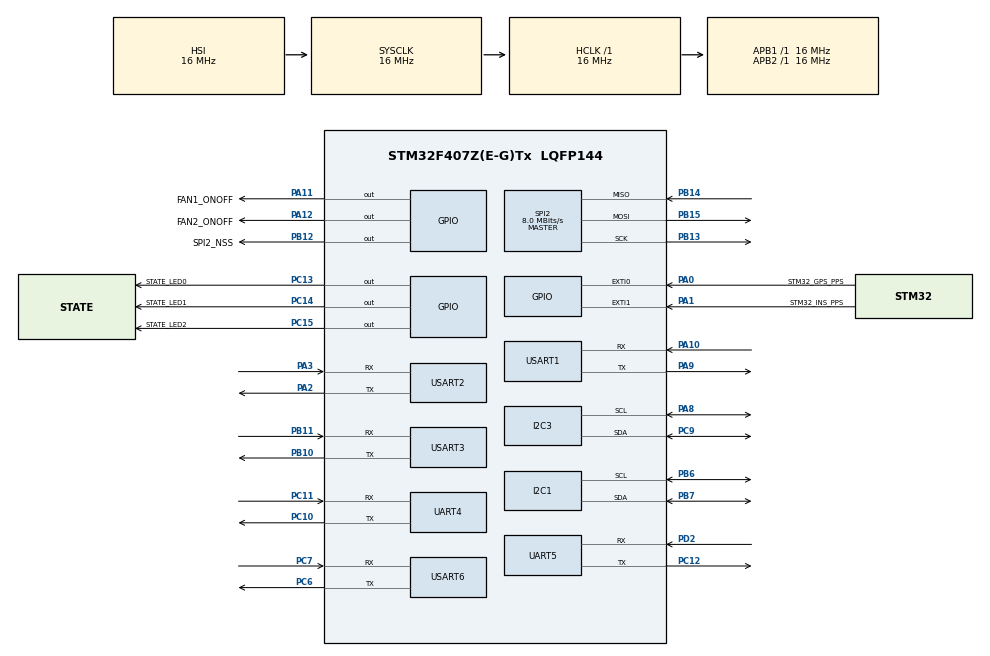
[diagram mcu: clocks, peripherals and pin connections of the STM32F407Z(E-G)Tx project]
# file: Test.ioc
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Mcu.Family=STM32F4
Mcu.Name=STM32F407Z(E-G)Tx
Mcu.Package=LQFP144
NVIC.PriorityGroup=NVIC_PRIORITYGROUP_4
NVIC.USART2_IRQn=true\:0\:0\:false\:false\:true\:true\:true\:true
PA0-WKUP.GPIO_Label=STM32_GPS_PPS
PA0-WKUP.Signal=GPXTI0
PA1.GPIO_Label=STM32_INS_PPS
PA1.Signal=GPXTI1
PA10.Mode=Asynchronous
PA10.Signal=USART1_RX
PA11.GPIO_Label=FAN1_ONOFF
PA11.Signal=GPIO_Output
PA12.GPIO_Label=FAN2_ONOFF
PA12.Signal=GPIO_Output
PA13.Mode=JTAG_5_pins
PA13.Signal=SYS_JTMS-SWDIO
PA14.Mode=JTAG_5_pins
PA14.Signal=SYS_JTCK-SWCLK
PA15.Mode=JTAG_5_pins
PA15.Signal=SYS_JTDI
PA2.Mode=Asynchronous
PA2.Signal=USART2_TX
PA3.Mode=Asynchronous
PA3.Signal=USART2_RX
PA8.Mode=I2C
PA8.Signal=I2C3_SCL
PA9.Mode=Asynchronous
PA9.Signal=USART1_TX
PB10.Mode=Asynchronous
PB10.Signal=USART3_TX
PB11.Mode=Asynchronous
PB11.Signal=USART3_RX
PB12.GPIO_Label=SPI2_NSS
PB12.Signal=GPIO_Output
PB13.Mode=Full_Duplex_Master
PB13.Signal=SPI2_SCK
PB14.Mode=Full_Duplex_Master
PB14.Signal=SPI2_MISO
PB15.Mode=Full_Duplex_Master
PB15.Signal=SPI2_MOSI
PB3.Mode=JTAG_5_pins
PB3.Signal=SYS_JTDO-SWO
PB4.Mode=JTAG_5_pins
PB4.Signal=SYS_JTRST
PB6.Mode=I2C
PB6.Signal=I2C1_SCL
PB7.Mode=I2C
PB7.Signal=I2C1_SDA
PC10.Mode=Asynchronous
PC10.Signal=UART4_TX
PC11.Mode=Asynchronous
PC11.Signal=UART4_RX
PC12.Mode=Asynchronous
PC12.Signal=UART5_TX
PC13-ANTI_TAMP.GPIO_Label=STATE_LED0
PC13-ANTI_TAMP.Signal=GPIO_Output
PC14-OSC32_IN.GPIO_Label=STATE_LED1
PC14-OSC32_IN.Signal=GPIO_Output
PC15-OSC32_OUT.GPIO_Label=STATE_LED2
PC15-OSC32_OUT.Signal=GPIO_Output
PC6.Mode=Asynchronous
PC6.Signal=USART6_TX
PC7.Mode=Asynchronous
PC7.Signal=USART6_RX
PC9.Mode=I2C
PC9.Signal=I2C3_SDA
PD2.Mode=Asynchronous
PD2.Signal=UART5_RX
PH0-OSC_IN.Mode=HSE-External-Oscillator
PH0-OSC_IN.Signal=RCC_OSC_IN
PH1-OSC_OUT.Mode=HSE-External-Oscillator
PH1-OSC_OUT.Signal=RCC_OSC_OUT
ProjectManager.HeapSize=0x200
ProjectManager.StackSize=0x400
ProjectManager.TargetToolchain=EWARM V8.32
RCC.AHBFreq_Value=16000000
RCC.APB1Freq_Value=16000000
RCC.APB2Freq_Value=16000000
RCC.CortexFreq_Value=16000000
RCC.HSE_VALUE=25000000
RCC.HSI_VALUE=16000000
RCC.LSE_VALUE=32768
RCC.SYSCLKFreq_VALUE=16000000
RCC.VCOOutputFreq_Value=192000000
SPI2.CalculateBaudRate=8.0 MBits/s
SPI2.Direction=SPI_DIRECTION_2LINES
SPI2.Mode=SPI_MODE_MASTER
SPI2.VirtualType=VM_MASTER
UART4.VirtualMode=Asynchronous
UART5.VirtualMode=Asynchronous
USART1.VirtualMode=VM_ASYNC
USART2.VirtualMode=VM_ASYNC
USART3.VirtualMode=VM_ASYNC
USART6.VirtualMode=VM_ASYNC
board=custom

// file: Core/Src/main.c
/* USER CODE BEGIN Header */
/**
  ******************************************************************************
  * @file           : main.c
  * @brief          : Main program body
  ******************************************************************************
  * @attention
  *
  * <h2><center>&copy; Copyright (c) 2022 STMicroelectronics.
  * All rights reserved.</center></h2>
  *
  * This software component is licensed by ST under BSD 3-Clause license,
  * the "License"; You may not use this file except in compliance with the
  * License. You may obtain a copy of the License at:
  *                        opensource.org/licenses/BSD-3-Clause
  *
  ******************************************************************************
  */
/* USER CODE END Header */
#include "main.h"

I2C_HandleTypeDef hi2c1;
I2C_HandleTypeDef hi2c3;

SPI_HandleTypeDef hspi2;

UART_HandleTypeDef huart4;
UART_HandleTypeDef huart5;
UART_HandleTypeDef huart1;
UART_HandleTypeDef huart2;
UART_HandleTypeDef huart3;
UART_HandleTypeDef huart6;

void SystemClock_Config(void);
static void MX_GPIO_Init(void);
static void MX_I2C3_Init(void);
static void MX_UART4_Init(void);
static void MX_UART5_Init(void);
static void MX_USART1_UART_Init(void);
static void MX_USART2_UART_Init(void);
static void MX_USART3_UART_Init(void);
static void MX_USART6_UART_Init(void);
static void MX_SPI2_Init(void);
static void MX_I2C1_Init(void);

/* USER CODE BEGIN 0 */
uint8_t USART_RX_FLAG = 0;
uint8_t temp_rx =0;
void HAL_UART_RxCpltCallback(UART_HandleTypeDef *huart)
{

  // USART1 Rx Interrupt
  if (huart->Instance == USART2) {
    USART_RX_FLAG = 1;
  HAL_UART_Receive_IT(&huart2, &temp_rx, 1);
}
}
/* USER CODE END 0 */

int main(void)
{

  /* MCU Configuration--------------------------------------------------------*/

  /* Reset of all peripherals, Initializes the Flash interface and the Systick. */
  HAL_Init();

  /* Configure the system clock */
  SystemClock_Config();

  /* Initialize all configured peripherals */
  MX_GPIO_Init();
  MX_I2C3_Init();
  MX_UART4_Init();
  MX_UART5_Init();
  MX_USART1_UART_Init();
  MX_USART2_UART_Init();
  MX_USART3_UART_Init();
  MX_USART6_UART_Init();
  MX_SPI2_Init();
  MX_I2C1_Init();
  /* USER CODE BEGIN 2 */
HAL_UART_Receive_IT(&huart2, &temp_rx, 1);
  /* USER CODE END 2 */
  /* Infinite loop */
  /* USER CODE BEGIN WHILE */
  while (1)
  {
    if(USART_RX_FLAG == 1){
      HAL_UART_Transmit(&huart2,&temp_rx,1,1);
      USART_RX_FLAG =0;
    }
    /* USER CODE END WHILE */

  }
}

void SystemClock_Config(void)
{
  RCC_OscInitTypeDef RCC_OscInitStruct = {0};
  RCC_ClkInitTypeDef RCC_ClkInitStruct = {0};

  /** Configure the main internal regulator output voltage
  */
  __HAL_RCC_PWR_CLK_ENABLE();
  __HAL_PWR_VOLTAGESCALING_CONFIG(PWR_REGULATOR_VOLTAGE_SCALE1);
  /** Initializes the RCC Oscillators according to the specified parameters
  * in the RCC_OscInitTypeDef structure.
  */
  RCC_OscInitStruct.OscillatorType = RCC_OSCILLATORTYPE_HSI;
  RCC_OscInitStruct.HSIState = RCC_HSI_ON;
  RCC_OscInitStruct.HSICalibrationValue = RCC_HSICALIBRATION_DEFAULT;
  RCC_OscInitStruct.PLL.PLLState = RCC_PLL_NONE;
  if (HAL_RCC_OscConfig(&RCC_OscInitStruct) != HAL_OK)
  {
    Error_Handler();
  }
  /** Initializes the CPU, AHB and APB buses clocks
  */
  RCC_ClkInitStruct.ClockType = RCC_CLOCKTYPE_HCLK|RCC_CLOCKTYPE_SYSCLK
                              |RCC_CLOCKTYPE_PCLK1|RCC_CLOCKTYPE_PCLK2;
  RCC_ClkInitStruct.SYSCLKSource = RCC_SYSCLKSOURCE_HSI;
  RCC_ClkInitStruct.AHBCLKDivider = RCC_SYSCLK_DIV1;
  RCC_ClkInitStruct.APB1CLKDivider = RCC_HCLK_DIV1;
  RCC_ClkInitStruct.APB2CLKDivider = RCC_HCLK_DIV1;

  if (HAL_RCC_ClockConfig(&RCC_ClkInitStruct, FLASH_LATENCY_0) != HAL_OK)
  {
    Error_Handler();
  }
}

static void MX_I2C1_Init(void)
{

  hi2c1.Instance = I2C1;
  hi2c1.Init.ClockSpeed = 100000;
  hi2c1.Init.DutyCycle = I2C_DUTYCYCLE_2;
  hi2c1.Init.OwnAddress1 = 0;
  hi2c1.Init.AddressingMode = I2C_ADDRESSINGMODE_7BIT;
  hi2c1.Init.DualAddressMode = I2C_DUALADDRESS_DISABLE;
  hi2c1.Init.OwnAddress2 = 0;
  hi2c1.Init.GeneralCallMode = I2C_GENERALCALL_DISABLE;
  hi2c1.Init.NoStretchMode = I2C_NOSTRETCH_DISABLE;
  if (HAL_I2C_Init(&hi2c1) != HAL_OK)
  {
    Error_Handler();
  }

}

static void MX_I2C3_Init(void)
{

  hi2c3.Instance = I2C3;
  hi2c3.Init.ClockSpeed = 100000;
  hi2c3.Init.DutyCycle = I2C_DUTYCYCLE_2;
  hi2c3.Init.OwnAddress1 = 0;
  hi2c3.Init.AddressingMode = I2C_ADDRESSINGMODE_7BIT;
  hi2c3.Init.DualAddressMode = I2C_DUALADDRESS_DISABLE;
  hi2c3.Init.OwnAddress2 = 0;
  hi2c3.Init.GeneralCallMode = I2C_GENERALCALL_DISABLE;
  hi2c3.Init.NoStretchMode = I2C_NOSTRETCH_DISABLE;
  if (HAL_I2C_Init(&hi2c3) != HAL_OK)
  {
    Error_Handler();
  }

}

static void MX_SPI2_Init(void)
{

  /* SPI2 parameter configuration*/
  hspi2.Instance = SPI2;
  hspi2.Init.Mode = SPI_MODE_MASTER;
  hspi2.Init.Direction = SPI_DIRECTION_2LINES;
  hspi2.Init.DataSize = SPI_DATASIZE_8BIT;
  hspi2.Init.CLKPolarity = SPI_POLARITY_LOW;
  hspi2.Init.CLKPhase = SPI_PHASE_1EDGE;
  hspi2.Init.NSS = SPI_NSS_SOFT;
  hspi2.Init.BaudRatePrescaler = SPI_BAUDRATEPRESCALER_2;
  hspi2.Init.FirstBit = SPI_FIRSTBIT_MSB;
  hspi2.Init.TIMode = SPI_TIMODE_DISABLE;
  hspi2.Init.CRCCalculation = SPI_CRCCALCULATION_DISABLE;
  hspi2.Init.CRCPolynomial = 10;
  if (HAL_SPI_Init(&hspi2) != HAL_OK)
  {
    Error_Handler();
  }

}

static void MX_UART4_Init(void)
{

  huart4.Instance = UART4;
  huart4.Init.BaudRate = 115200;
  huart4.Init.WordLength = UART_WORDLENGTH_8B;
  huart4.Init.StopBits = UART_STOPBITS_1;
  huart4.Init.Parity = UART_PARITY_NONE;
  huart4.Init.Mode = UART_MODE_TX_RX;
  huart4.Init.HwFlowCtl = UART_HWCONTROL_NONE;
  huart4.Init.OverSampling = UART_OVERSAMPLING_16;
  if (HAL_UART_Init(&huart4) != HAL_OK)
  {
    Error_Handler();
  }

}

static void MX_UART5_Init(void)
{

  huart5.Instance = UART5;
  huart5.Init.BaudRate = 115200;
  huart5.Init.WordLength = UART_WORDLENGTH_8B;
  huart5.Init.StopBits = UART_STOPBITS_1;
  huart5.Init.Parity = UART_PARITY_NONE;
  huart5.Init.Mode = UART_MODE_TX_RX;
  huart5.Init.HwFlowCtl = UART_HWCONTROL_NONE;
  huart5.Init.OverSampling = UART_OVERSAMPLING_16;
  if (HAL_UART_Init(&huart5) != HAL_OK)
  {
    Error_Handler();
  }

}

static void MX_USART1_UART_Init(void)
{

  huart1.Instance = USART1;
  huart1.Init.BaudRate = 115200;
  huart1.Init.WordLength = UART_WORDLENGTH_8B;
  huart1.Init.StopBits = UART_STOPBITS_1;
  huart1.Init.Parity = UART_PARITY_NONE;
  huart1.Init.Mode = UART_MODE_TX_RX;
  huart1.Init.HwFlowCtl = UART_HWCONTROL_NONE;
  huart1.Init.OverSampling = UART_OVERSAMPLING_16;
  if (HAL_UART_Init(&huart1) != HAL_OK)
  {
    Error_Handler();
  }

}

static void MX_USART2_UART_Init(void)
{

  huart2.Instance = USART2;
  huart2.Init.BaudRate = 115200;
  huart2.Init.WordLength = UART_WORDLENGTH_8B;
  huart2.Init.StopBits = UART_STOPBITS_1;
  huart2.Init.Parity = UART_PARITY_NONE;
  huart2.Init.Mode = UART_MODE_TX_RX;
  huart2.Init.HwFlowCtl = UART_HWCONTROL_NONE;
  huart2.Init.OverSampling = UART_OVERSAMPLING_16;
  if (HAL_UART_Init(&huart2) != HAL_OK)
  {
    Error_Handler();
  }

}

static void MX_USART3_UART_Init(void)
{

  huart3.Instance = USART3;
  huart3.Init.BaudRate = 115200;
  huart3.Init.WordLength = UART_WORDLENGTH_8B;
  huart3.Init.StopBits = UART_STOPBITS_1;
  huart3.Init.Parity = UART_PARITY_NONE;
  huart3.Init.Mode = UART_MODE_TX_RX;
  huart3.Init.HwFlowCtl = UART_HWCONTROL_NONE;
  huart3.Init.OverSampling = UART_OVERSAMPLING_16;
  if (HAL_UART_Init(&huart3) != HAL_OK)
  {
    Error_Handler();
  }

}

static void MX_USART6_UART_Init(void)
{

  huart6.Instance = USART6;
  huart6.Init.BaudRate = 115200;
  huart6.Init.WordLength = UART_WORDLENGTH_8B;
  huart6.Init.StopBits = UART_STOPBITS_1;
  huart6.Init.Parity = UART_PARITY_NONE;
  huart6.Init.Mode = UART_MODE_TX_RX;
  huart6.Init.HwFlowCtl = UART_HWCONTROL_NONE;
  huart6.Init.OverSampling = UART_OVERSAMPLING_16;
  if (HAL_UART_Init(&huart6) != HAL_OK)
  {
    Error_Handler();
  }

}

static void MX_GPIO_Init(void)
{
  GPIO_InitTypeDef GPIO_InitStruct = {0};

  /* GPIO Ports Clock Enable */
  __HAL_RCC_GPIOC_CLK_ENABLE();
  __HAL_RCC_GPIOH_CLK_ENABLE();
  __HAL_RCC_GPIOA_CLK_ENABLE();
  __HAL_RCC_GPIOB_CLK_ENABLE();
  __HAL_RCC_GPIOD_CLK_ENABLE();

  /*Configure GPIO pin Output Level */
  HAL_GPIO_WritePin(GPIOC, STATE_LED0_Pin|STATE_LED1_Pin|STATE_LED2_Pin, GPIO_PIN_RESET);

  /*Configure GPIO pin Output Level */
  HAL_GPIO_WritePin(SPI2_NSS_GPIO_Port, SPI2_NSS_Pin, GPIO_PIN_RESET);

  /*Configure GPIO pin Output Level */
  HAL_GPIO_WritePin(GPIOA, FAN1_ONOFF_Pin|FAN2_ONOFF_Pin, GPIO_PIN_RESET);

  /*Configure GPIO pins : STATE_LED0_Pin STATE_LED1_Pin STATE_LED2_Pin */
  GPIO_InitStruct.Pin = STATE_LED0_Pin|STATE_LED1_Pin|STATE_LED2_Pin;
  GPIO_InitStruct.Mode = GPIO_MODE_OUTPUT_PP;
  GPIO_InitStruct.Pull = GPIO_NOPULL;
  GPIO_InitStruct.Speed = GPIO_SPEED_FREQ_LOW;
  HAL_GPIO_Init(GPIOC, &GPIO_InitStruct);

  /*Configure GPIO pins : STM32_GPS_PPS_Pin STM32_INS_PPS_Pin */
  GPIO_InitStruct.Pin = STM32_GPS_PPS_Pin|STM32_INS_PPS_Pin;
  GPIO_InitStruct.Mode = GPIO_MODE_IT_RISING;
  GPIO_InitStruct.Pull = GPIO_NOPULL;
  HAL_GPIO_Init(GPIOA, &GPIO_InitStruct);

  /*Configure GPIO pin : SPI2_NSS_Pin */
  GPIO_InitStruct.Pin = SPI2_NSS_Pin;
  GPIO_InitStruct.Mode = GPIO_MODE_OUTPUT_PP;
  GPIO_InitStruct.Pull = GPIO_NOPULL;
  GPIO_InitStruct.Speed = GPIO_SPEED_FREQ_LOW;
  HAL_GPIO_Init(SPI2_NSS_GPIO_Port, &GPIO_InitStruct);

  /*Configure GPIO pins : FAN1_ONOFF_Pin FAN2_ONOFF_Pin */
  GPIO_InitStruct.Pin = FAN1_ONOFF_Pin|FAN2_ONOFF_Pin;
  GPIO_InitStruct.Mode = GPIO_MODE_OUTPUT_PP;
  GPIO_InitStruct.Pull = GPIO_NOPULL;
  GPIO_InitStruct.Speed = GPIO_SPEED_FREQ_LOW;
  HAL_GPIO_Init(GPIOA, &GPIO_InitStruct);

}

void Error_Handler(void)
{
  __disable_irq();
  while (1)
  {
  }
}

/************************ (C) COPYRIGHT STMicroelectronics *****END OF FILE****/
